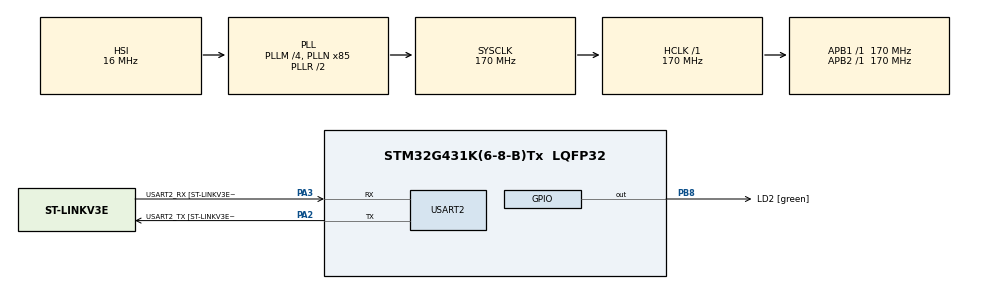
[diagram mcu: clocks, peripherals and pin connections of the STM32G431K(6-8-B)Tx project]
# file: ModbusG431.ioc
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FREERTOS.Tasks01=defaultTask,24,256,StartDefaultTask,Default,NULL,Dynamic,NULL,NULL
FREERTOS.configMINIMAL_STACK_SIZE=256
FREERTOS.configUSE_NEWLIB_REENTRANT=1
Mcu.Family=STM32G4
Mcu.Name=STM32G431K(6-8-B)Tx
Mcu.Package=LQFP32
NVIC.PriorityGroup=NVIC_PRIORITYGROUP_4
NVIC.TIM1_TRG_COM_TIM17_IRQn=true\:15\:0\:false\:false\:true\:false\:false\:true\:true
NVIC.TimeBase=TIM1_TRG_COM_TIM17_IRQn
NVIC.TimeBaseIP=TIM17
NVIC.USART2_IRQn=true\:5\:0\:false\:false\:true\:true\:true\:true\:true
PA13.GPIO_Label=T_SWDIO
PA13.Mode=Serial_Wire
PA13.Signal=SYS_JTMS-SWDIO
PA14.GPIO_Label=T_SWCLK
PA14.Mode=Serial_Wire
PA14.Signal=SYS_JTCK-SWCLK
PA2.GPIO_Label=USART2_TX [ST-LINKV3E_VCP_RX]
PA2.Mode=Asynchronous
PA2.Signal=USART2_TX
PA3.GPIO_Label=USART2_RX [ST-LINKV3E_VCP_TX]
PA3.Mode=Asynchronous
PA3.Signal=USART2_RX
PB3.GPIO_Label=T_SWO
PB3.Signal=SYS_JTDO-SWO
PB8-BOOT0.GPIO_Label=LD2 [green]
PB8-BOOT0.Signal=GPIO_Output
ProjectManager.HeapSize=0x200
ProjectManager.StackSize=0x400
ProjectManager.TargetToolchain=STM32CubeIDE
RCC.ADC12Freq_Value=170000000
RCC.AHBFreq_Value=170000000
RCC.APB1Freq_Value=170000000
RCC.APB1TimFreq_Value=170000000
RCC.APB2Freq_Value=170000000
RCC.APB2TimFreq_Value=170000000
RCC.CortexFreq_Value=170000000
RCC.EXTERNAL_CLOCK_VALUE=12288000
RCC.HCLKFreq_Value=170000000
RCC.HSE_VALUE=8000000
RCC.HSI48_VALUE=48000000
RCC.HSI_VALUE=16000000
RCC.LSE_VALUE=32768
RCC.PLLM=RCC_PLLM_DIV4
RCC.PLLN=85
RCC.SYSCLKFreq_VALUE=170000000
RCC.SYSCLKSource=RCC_SYSCLKSOURCE_PLLCLK
RCC.USBFreq_Value=170000000
RCC.VCOOutputFreq_Value=340000000
USART2.VirtualMode-Asynchronous=VM_ASYNC
USART2.WordLength=WORDLENGTH_8B
VP_FREERTOS_VS_CMSIS_V2.Mode=CMSIS_V2
VP_SYS_VS_DBSignals.Mode=DisableDeadBatterySignals
VP_SYS_VS_tim17.Mode=TIM17
board=NUCLEO-G431KB

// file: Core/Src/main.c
/* USER CODE BEGIN Header */
/**
  ******************************************************************************
  * @file           : main.c
  * @brief          : Main program body
  ******************************************************************************
  * @attention
  *
  * Copyright (c) 2024 STMicroelectronics.
  * All rights reserved.
  *
  * This software is licensed under terms that can be found in the LICENSE file
  * in the root directory of this software component.
  * If no LICENSE file comes with this software, it is provided AS-IS.
  *
  ******************************************************************************
  */
/* USER CODE END Header */
#include "main.h"
#include "cmsis_os.h"
#include "usart.h"
#include "gpio.h"

/* USER CODE BEGIN Includes */
#include "Modbus.h"
/* USER CODE END Includes */

/* USER CODE BEGIN PTD */
modbusHandler_t ModbusH;
//uint16_t ModbusDATA[8];

// Separate memory arrays per block type
uint16_t CoilsDATA[2];        // 32 coils,  addresses   0 –  31
uint16_t DiDATA[2];           // 32 DI,     addresses 100 – 131
uint16_t HoldingDATA[4];      // 4 HR,      addresses 200 – 203
uint16_t InputDATA[4];        // 4 IR,      addresses 300 – 303

/* USER CODE END PTD */

void SystemClock_Config(void);
void MX_FREERTOS_Init(void);

int main(void)
{

  /* MCU Configuration--------------------------------------------------------*/

  /* Reset of all peripherals, Initializes the Flash interface and the Systick. */
  HAL_Init();

  /* Configure the system clock */
  SystemClock_Config();

  /* Initialize all configured peripherals */
  MX_GPIO_Init();
  MX_USART2_UART_Init();
  /* USER CODE BEGIN 2 */

  //Initialize Modbus library
  ModbusH.uModbusType  = MB_SLAVE;
  ModbusH.port         = &huart2;
  ModbusH.u8id         = 1;
  ModbusH.u16timeOut   = 1000;
  ModbusH.EN_Port      = NULL;
  ModbusH.u16regs      = NULL;   // not used — separate regions active
  ModbusH.u16regsize   = 0;
  ModbusH.xTypeHW      = USART_HW;

  // Coils — FC1, FC5, FC15
  ModbusH.u16coils            = CoilsDATA;
  ModbusH.u16coilsStartAdd    = 0;
  ModbusH.u16coilsNregs       = 2;   // 32 coils

  // Discrete Inputs — FC2
  ModbusH.u16discreteInputs           = DiDATA;
  ModbusH.u16discreteInputsStartAdd   = 100;
  ModbusH.u16discreteInputsNregs      = 2;   // 32 DI

  // Holding Registers — FC3, FC6, FC16
  ModbusH.u16holdingRegs          = HoldingDATA;
  ModbusH.u16holdingRegsStartAdd  = 200;
  ModbusH.u16holdingRegsNregs     = 4;

  // Input Registers — FC4
  ModbusH.u16inputRegs            = InputDATA;
  ModbusH.u16inputRegsStartAdd    = 300;
  ModbusH.u16inputRegsNregs       = 4;

  ModbusInit(&ModbusH);
  //Start capturing traffic on serial Port
  ModbusStart(&ModbusH);
  /* USER CODE END 2 */

  /* Init scheduler */
  osKernelInitialize();

  /* Call init function for freertos objects (in cmsis_os2.c) */
  MX_FREERTOS_Init();

  /* Start scheduler */
  osKernelStart();

  /* We should never get here as control is now taken by the scheduler */

  /* Infinite loop */
  while (1)
  {

  }
}

void SystemClock_Config(void)
{
  RCC_OscInitTypeDef RCC_OscInitStruct = {0};
  RCC_ClkInitTypeDef RCC_ClkInitStruct = {0};

  /** Configure the main internal regulator output voltage
  */
  HAL_PWREx_ControlVoltageScaling(PWR_REGULATOR_VOLTAGE_SCALE1_BOOST);

  /** Initializes the RCC Oscillators according to the specified parameters
  * in the RCC_OscInitTypeDef structure.
  */
  RCC_OscInitStruct.OscillatorType = RCC_OSCILLATORTYPE_HSI;
  RCC_OscInitStruct.HSIState = RCC_HSI_ON;
  RCC_OscInitStruct.HSICalibrationValue = RCC_HSICALIBRATION_DEFAULT;
  RCC_OscInitStruct.PLL.PLLState = RCC_PLL_ON;
  RCC_OscInitStruct.PLL.PLLSource = RCC_PLLSOURCE_HSI;
  RCC_OscInitStruct.PLL.PLLM = RCC_PLLM_DIV4;
  RCC_OscInitStruct.PLL.PLLN = 85;
  RCC_OscInitStruct.PLL.PLLP = RCC_PLLP_DIV2;
  RCC_OscInitStruct.PLL.PLLQ = RCC_PLLQ_DIV2;
  RCC_OscInitStruct.PLL.PLLR = RCC_PLLR_DIV2;
  if (HAL_RCC_OscConfig(&RCC_OscInitStruct) != HAL_OK)
  {
    Error_Handler();
  }

  /** Initializes the CPU, AHB and APB buses clocks
  */
  RCC_ClkInitStruct.ClockType = RCC_CLOCKTYPE_HCLK|RCC_CLOCKTYPE_SYSCLK
                              |RCC_CLOCKTYPE_PCLK1|RCC_CLOCKTYPE_PCLK2;
  RCC_ClkInitStruct.SYSCLKSource = RCC_SYSCLKSOURCE_PLLCLK;
  RCC_ClkInitStruct.AHBCLKDivider = RCC_SYSCLK_DIV1;
  RCC_ClkInitStruct.APB1CLKDivider = RCC_HCLK_DIV1;
  RCC_ClkInitStruct.APB2CLKDivider = RCC_HCLK_DIV1;

  if (HAL_RCC_ClockConfig(&RCC_ClkInitStruct, FLASH_LATENCY_4) != HAL_OK)
  {
    Error_Handler();
  }
}

void HAL_TIM_PeriodElapsedCallback(TIM_HandleTypeDef *htim)
{
  if (htim->Instance == TIM17) {
    HAL_IncTick();
  }
}

void Error_Handler(void)
{
  __disable_irq();
  while (1)
  {
  }
}

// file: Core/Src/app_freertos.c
/* USER CODE BEGIN Header */
/**
  ******************************************************************************
  * File Name          : app_freertos.c
  * Description        : Code for freertos applications
  ******************************************************************************
  * @attention
  *
  * Copyright (c) 2024 STMicroelectronics.
  * All rights reserved.
  *
  * This software is licensed under terms that can be found in the LICENSE file
  * in the root directory of this software component.
  * If no LICENSE file comes with this software, it is provided AS-IS.
  *
  ******************************************************************************
  */
/* USER CODE END Header */

#include "FreeRTOS.h"
#include "task.h"
#include "main.h"
#include "cmsis_os.h"

/* Definitions for defaultTask */
osThreadId_t defaultTaskHandle;
const osThreadAttr_t defaultTask_attributes = {
  .name = "defaultTask",
  .priority = (osPriority_t) osPriorityNormal,
  .stack_size = 256 * 4
};

/* USER CODE BEGIN FunctionPrototypes */
modbus_t telegram[2];
/* USER CODE END FunctionPrototypes */

void StartDefaultTask(void *argument);

void MX_FREERTOS_Init(void); /* (MISRA C 2004 rule 8.1) */

void MX_FREERTOS_Init(void) {

  /* Create the thread(s) */
  /* creation of defaultTask */
  defaultTaskHandle = osThreadNew(StartDefaultTask, NULL, &defaultTask_attributes);

}

void StartDefaultTask(void *argument)
{
  /* USER CODE BEGIN StartDefaultTask */
  /* Infinite loop */
	/*
	uint32_t u32NotificationValue;
	telegram[0].u8id = 1; // slave address
	telegram[0].u8fct = MB_FC_WRITE_REGISTER; // function code (this one is registers read)
	telegram[0].u16RegAdd = 0x0; // start address in slave
	telegram[0].u16CoilsNo = 1; // number of elements (coils or registers) to read
	telegram[0].u16reg = ModbusDATA; // pointer to a memory array

    telegram[1].u8id = 1; // slave address
	telegram[1].u8fct = MB_FC_READ_REGISTERS; // function code (this one is registers read)
	telegram[1].u16RegAdd = 0x0; // start address in slave
	telegram[1].u16CoilsNo = 1; // number of elements (coils or registers) to read
	telegram[1].u16reg = ModbusDATA; // pointer to a memory array
	ModbusDATA[0] =1;
*/

  uint16_t delayCount = 1000;
  /* Infinite loop */
  for(;;)
  {
		/*   this section is for the slave example 	*/

	    HAL_GPIO_TogglePin(LD2_GPIO_Port, LD2_Pin);
/*
		if (ModbusDATA[0])
		{
			delayCount = ModbusDATA[0];
		}
		else
		{
			delayCount = 250;
		}*/

		osDelay(delayCount);

		/* this section is for the master section */

	 	//ModbusQuery(&ModbusH, telegram[1]); // make a query
	 	//u32NotificationValue = ulTaskNotifyTake(pdTRUE, portMAX_DELAY ); // block until query finishes

	  /*
	  u32NotificationValue = ModbusQueryV2(&ModbusH, telegram[1]); // make a query with the new function ModbusQueryV2 prototype
	    if(u32NotificationValue != OP_OK_QUERY )
	 	{
	 	  		//handle error
	 	  		//  while(1);
	 		u32NotificationValue = 0;
	 	}

	 	osDelay(delayCount);

	 	ModbusDATA[0] = ModbusDATA[0] + 1;
	 	ModbusQuery(&ModbusH, telegram[0]); // make a query with old function
	 	u32NotificationValue = ulTaskNotifyTake(pdTRUE, portMAX_DELAY ); // block until query finishes this is embedded in V2
        if(u32NotificationValue != OP_OK_QUERY)
	 	{
	 	  		//handle error
	 	   	  	//  while(1);
        	u32NotificationValue = 0;
	 	}
*/

  }

  /* USER CODE END StartDefaultTask */
}
